# LPC43xx register map
File version: 5
Registers are 32-bit, read-write, reset 0x0 unless marked. A register's access mark holds for its fields unless they carry their own. Offsets are from the block's base; [hi:lo] are bit positions; {n}, {i} and the like mark numbered series.

## SGPIO — Product name title=UM10503 Chapter title=LPC43xx Serial GPIO (SGPIO) Modification date=10/7/2011 Major revision=0 Minor revision=3
Base 0x40101000
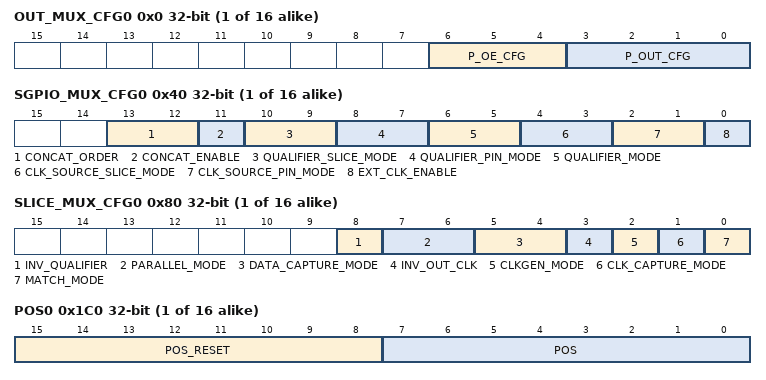
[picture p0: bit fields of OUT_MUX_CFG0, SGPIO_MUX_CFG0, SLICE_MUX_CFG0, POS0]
{0x0+4i} OUT_MUX_CFG{i} (i=0..15) — Pin multiplexer configuration registers.
  [6:4] P_OE_CFG — Output enable source. All other values are reserved.
    0=GPIO_OE_STATE_SET_B (gpio_oe (state set by GPIO_OEREG)); 4=DOUT_OEM1_1_BIT_MOD (dout_oem1 (1-bit mode)); 5=DOUT_OEM2_2_BIT_MOD (dout_oem2 (2-bit mode)); 6=DOUT_OEM4_4_BIT_MOD (dout_oem4 (4-bit mode)); 7=DOUT_OEM8_8_BIT_MOD (dout_oem8 (8-bit mode))
  [3:0] P_OUT_CFG — Output control of output SGPIOn. All other values are reserved.
    0=DOUT_DOUTM1_1_BIT_M (dout_doutm1 (1-bit mode)); 1=DOUT_DOUTM2A_2_BIT_ (dout_doutm2a (2-bit mode 2a)); 2=DOUT_DOUTM2B_2_BIT_ (dout_doutm2b (2-bit mode 2b)); 3=DOUT_DOUTM2C_2_BIT_ (dout_doutm2c (2-bit mode 2c)); 4=GPIO_OUT_LEVEL_SET_ (gpio_out (level set by GPIO_OUTREG)); 5=DOUT_DOUTM4A_4_BIT_ (dout_doutm4a (4-bit mode 4a)); 6=DOUT_DOUTM4B_4_BIT_ (dout_doutm4b (4-bit mode 4b)); 7=DOUT_DOUTM4C_4_BIT_ (dout_doutm4c (4-bit mode 4c)); 8=CLK_OUT; 9=DOUT_DOUTM8A_8_BIT_ (dout_doutm8a (8-bit mode 8a)); 10=DOUT_DOUTM8B_8_BIT_ (dout_doutm8b (8-bit mode 8b)); 11=DOUT_DOUTM8C_8_BIT_ (dout_doutm8c (8-bit mode 8c))
{0x40+4i} SGPIO_MUX_CFG{i} (i=0..15) — SGPIO multiplexer configuration registers.
  [13:12] CONCAT_ORDER — Select concatenation order
    0=SELF_LOOP; 1=2_SLICES; 2=4_SLICES; 3=8_SLICES
  [11] CONCAT_ENABLE — Enable concatenation.
    0=EXTERNAL_DATA_PIN; 1=CONCATENATE_DATA
  [10:9] QUALIFIER_SLICE_MODE — Select qualifier slice.
    0=SLICE_A (Slice A, but for slice A slice D is used.); 1=SLICE_H (Slice H, but for slice H slice O is used.); 2=SLICE_I (Slice I, but for slice I slice D is used.); 3=SLICE_P (Slice P, but for slice P slice O is used.)
  [8:7] QUALIFIER_PIN_MODE — Select qualifier pin.
    {v}=SGPIO{v+8} (v=0..3)
  [6:5] QUALIFIER_MODE — Select qualifier mode.
    0=ENABLE; 1=DISABLE; 2=SLICE_SEE_BITS_QUAL (Slice (see bits QUALIFIER_SLICE_MODE in this register)); 3=EXTERNAL_SGPIO_PIN_ (External SGPIO pin (8, 9, 10, or 11))
  [4:3] CLK_SOURCE_SLICE_MODE — Select clock source slice. Note that slices D, H, O and P do not support this mode.
    0=SLICE_D; 1=SLICE_H; 2=SLICE_O; 3=SLICE_P
  [2:1] CLK_SOURCE_PIN_MODE — Select source clock pin.
    {v}=SGPIO{v+8} (v=0..3)
  [0] EXT_CLK_ENABLE — Select clock signal.
    0=INTERNAL_CLOCK_SIGNA (Internal clock signal (slice)); 1=EXTERNAL_CLOCK_SIGNA (External clock signal (pin))
{0x80+4i} SLICE_MUX_CFG{i} (i=0..15) — Slice multiplexer configuration registers.
  [8] INV_QUALIFIER — Inversion qualifier
    0=USE_NORMAL_QUALIFIER; 1=USE_INVERTED_QUALIFI (Use inverted qualifier.)
  [7:6] PARALLEL_MODE
    0=SHIFT_1_BIT_PER_CLOC (Shift 1 bit per clock.); 1=SHIFT_2_BITS_PER_CLO (Shift 2 bits per clock.); 2=SHIFT_4_BITS_PER_CLO (Shift 4 bits per clock.); 3=SHIFT_1_BYTE_PER_CLO (Shift 1 byte per clock.)
  [5:4] DATA_CAPTURE_MODE — Condition for input bit match interrupt
    0=DETECT_RISING_EDGE_; 1=DETECT_FALLING_EDGE_; 2=DETECT_LOW_LEVEL_; 3=DETECT_HIGH_LEVEL_
  [3] INV_OUT_CLK — Invert output clock
    0=NORMAL_CLOCK_; 1=INVERTED_CLOCK_
  [2] CLKGEN_MODE — Clock generation mode
    0=USE_CLOCK_INTERNALLY (Use clock internally generated by COUNTER.); 1=USE_EXTERNAL_CLOCK_F (Use external clock from a pin or other slice.)
  [1] CLK_CAPTURE_MODE — Capture clock mode
    0=USE_RISING_CLOCK_EDG (Use rising clock edge.); 1=USE_FALLING_CLOCK_ED (Use falling clock edge.)
  [0] MATCH_MODE
    0=DO_NOT_MATCH_DATA_; 1=MATCH_DATA_
{0xC0+4i} REG{i} (i=0..15) — Slice data registers. Each time COUNT0 reaches 0x0 the register shifts loading bit 31 with data captured from DIN(n). DOUT(n) is set to REG(0)
  [31:0] REG — At each active shift clock the register shifts right; loading REG(31) with data captured from DIN(n) and DOUT(n) is set to REG(0).
{0x100+4i} REG_SS{i} (i=0..15) — Slice data shadow registers. Each time POS reaches 0x0 the contents of REG_SS is exchanged with the content of REG
  [31:0] REG_SS — Each time POS reaches 0x0 the contents of REG_SS is exchanged with the content of REG.
{0x140+4i} PRESET{i} (i=0..15) — Reload value of COUNT0, loaded when COUNT0 reaches 0x0
  [11:0] PRESET — Counter reload value; loaded when COUNT reaches 0x0.
{0x180+4i} COUNT{i} (i=0..15) — Down counter, counts down each clock cycle.
  [11:0] COUNT — Down counter, counts down each shift clock cycle. Next count after 0x0 is PRESET.
{0x1C0+4i} POS{i} (i=0..15) — Each time COUNT0 reaches 0x0
  [15:8] POS_RESET — Reload value for POS after POS reaches 0x0.
  [7:0] POS — Each time COUNT reaches 0x0 POS counts down.
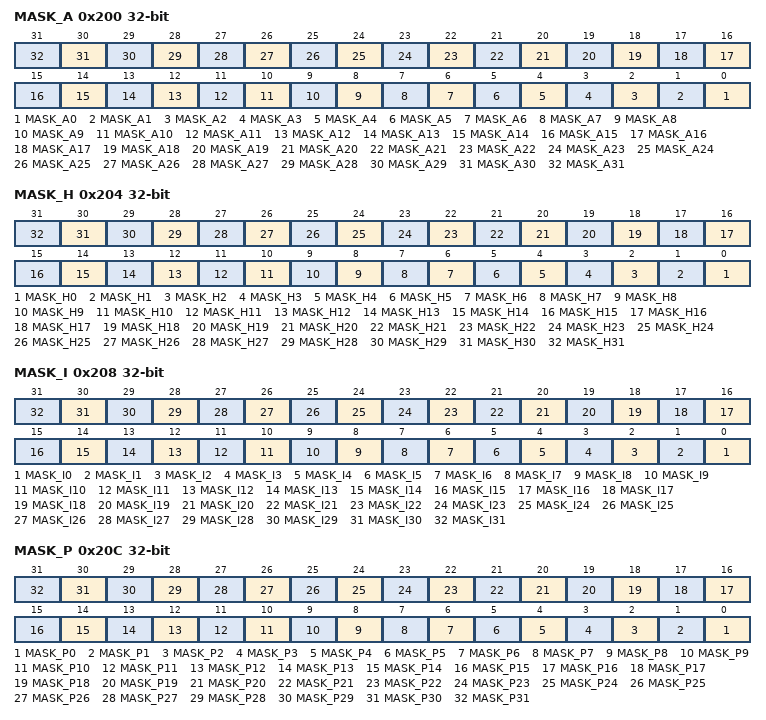
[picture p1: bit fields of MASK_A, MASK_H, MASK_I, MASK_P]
0x200 MASK_A — Mask for pattern match function of slice A
  [n] MASK_A{n} (n=0..31) — Mask for pattern match function of slice A 0 = No effect. 1 = Mask this bit.
0x204 MASK_H — Mask for pattern match function of slice H
  [n] MASK_H{n} (n=0..31) — Mask for pattern match function of slice H 0 = No effect. 1 = Mask this bit.
0x208 MASK_I — Mask for pattern match function of slice I
  [n] MASK_I{n} (n=0..31) — Mask for pattern match function of slice I 0 = No effect . 1 = Mask this bit.
0x20C MASK_P — Mask for pattern match function of slice P
  [n] MASK_P{n} (n=0..31) — Mask for pattern match function of slice P 0 = No effect. 1 = Mask this bit.
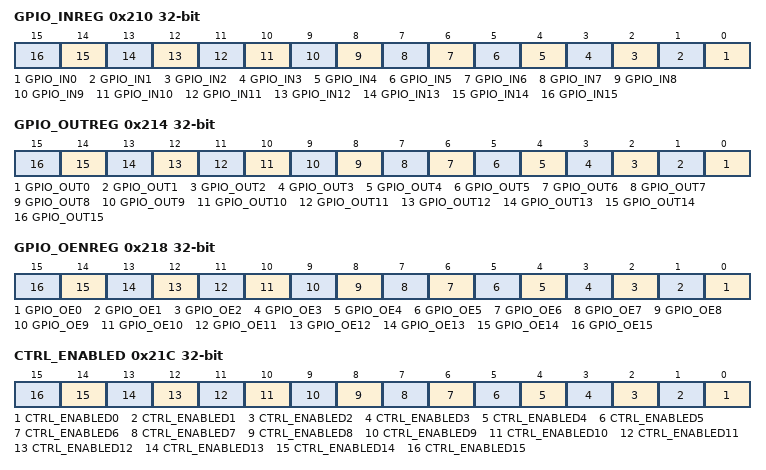
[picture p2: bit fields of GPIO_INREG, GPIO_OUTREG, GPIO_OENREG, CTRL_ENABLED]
0x210 GPIO_INREG ro — GPIO input status register
  [n] GPIO_IN{n} (n=0..15) — Bit i reflects the input state of SGPIO pin i . 0 = LOW 1 = HIGH
0x214 GPIO_OUTREG — GPIO output control register
  [n] GPIO_OUT{n} (n=0..15) — GPIO output register. Bit i sets the output of SGPIO pin i. 0 = LOW 1 = HIGH
0x218 GPIO_OENREG — GPIO OE control register
  [n] GPIO_OE{n} (n=0..15) — Bit i selects the output enable state of SGPIO pin i. 0 = GPIO output i is tri-state . 1 = GPIO output i is active.
0x21C CTRL_ENABLED — Enables the slice COUNT counter
  [n] CTRL_ENABLED{n} (n=0..15) — Slice count enable. Bit n controls slice n (0 = slice A, ..., 15 = slice P). 0 = . 1 = Enables COUNTn.
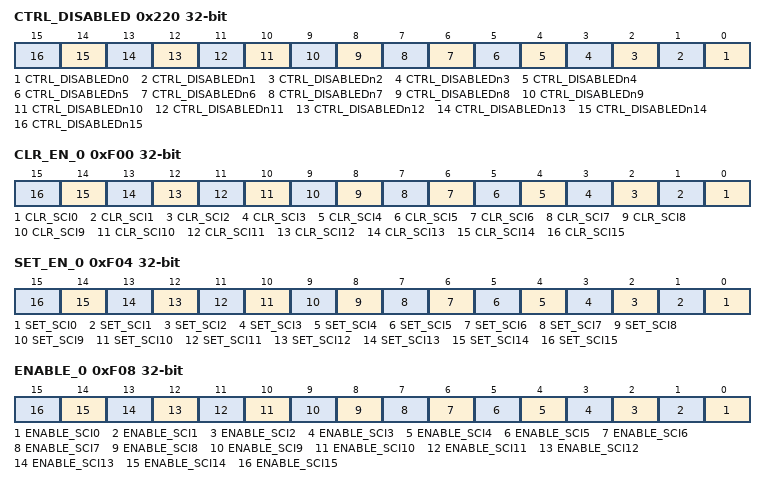
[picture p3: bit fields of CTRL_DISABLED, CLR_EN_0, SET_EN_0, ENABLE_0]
0x220 CTRL_DISABLED — Disables the slice COUNT counter
  [n] CTRL_DISABLEDn{n} (n=0..15) — Slice count disable. Bit n controls slice n, (0 = slice A, ..., 15 = slice P). 0 = 1 = Disables COUNTn.
0xF00 CLR_EN_0 wo — Shift clock interrupt clear mask
  [n] CLR_SCI{n} (n=0..15) — 1 = Shift clock interrupt clear mask of slice n.
0xF04 SET_EN_0 wo — Shift clock interrupt set mask
  [n] SET_SCI{n} (n=0..15) — 1 = Shift clock interrupt set mask of slice n.
0xF08 ENABLE_0 ro — Shift clock interrupt enable
  [n] ENABLE_SCI{n} (n=0..15) — 1 = Shift clock interrupt enable of slice n.
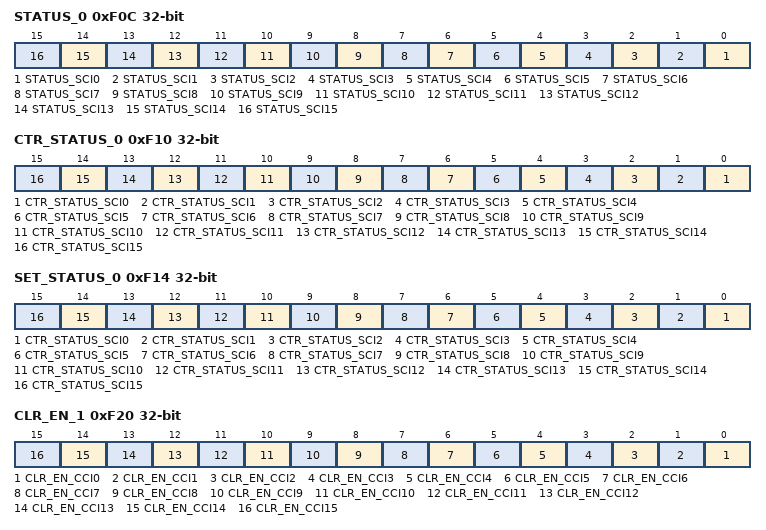
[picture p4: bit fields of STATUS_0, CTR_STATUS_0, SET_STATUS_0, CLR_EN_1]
0xF0C STATUS_0 ro — Shift clock interrupt status
  [n] STATUS_SCI{n} (n=0..15) — Shift clock interrupt status of slice n.
0xF10 CTR_STATUS_0 wo — Shift clock interrupt clear status
  [n] CTR_STATUS_SCI{n} (n=0..15) — Shift clock interrupt clear status of slice n.
0xF14 SET_STATUS_0 wo — Shift clock interrupt set status
  [n] CTR_STATUS_SCI{n} (n=0..15) — Shift clock interrupt set status of slice n.
0xF20 CLR_EN_1 wo — Capture clock interrupt clear mask
  [n] CLR_EN_CCI{n} (n=0..15) — 1 = Capture clock interrupt clear mask of slice n.
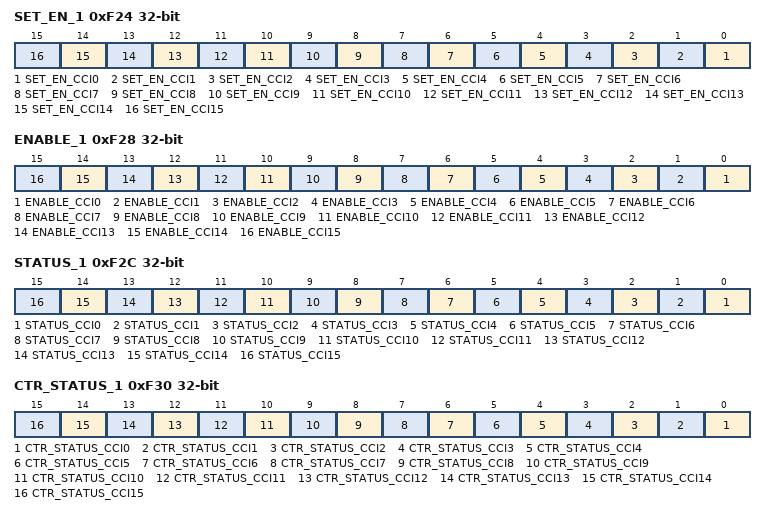
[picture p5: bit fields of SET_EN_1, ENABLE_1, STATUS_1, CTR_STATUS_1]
0xF24 SET_EN_1 wo — Capture clock interrupt set mask
  [n] SET_EN_CCI{n} (n=0..15) — 1 = Capture clock interrupt set mask of slice n.
0xF28 ENABLE_1 ro — Capture clock interrupt enable
  [n] ENABLE_CCI{n} (n=0..15) — Capture clock interrupt enable of slice n.
0xF2C STATUS_1 ro — Capture clock interrupt status
  [n] STATUS_CCI{n} (n=0..15) — Capture clock interrupt status of slice n.
0xF30 CTR_STATUS_1 wo — Capture clock interrupt clear status
  [n] CTR_STATUS_CCI{n} (n=0..15) — Capture clock interrupt clear status of slice n.
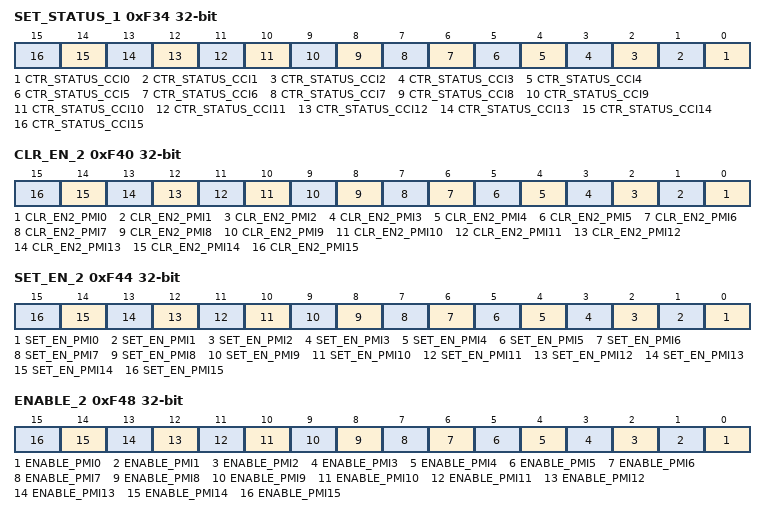
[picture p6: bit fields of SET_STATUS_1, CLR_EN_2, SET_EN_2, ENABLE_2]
0xF34 SET_STATUS_1 wo — Capture clock interrupt set status
  [n] CTR_STATUS_CCI{n} (n=0..15) — Capture clock interrupt set status of slice n.
0xF40 CLR_EN_2 wo — Pattern match interrupt clear mask
  [n] CLR_EN2_PMI{n} (n=0..15) — 1 = Match interrupt clear mask of slice n.
0xF44 SET_EN_2 wo — Pattern match interrupt set mask
  [n] SET_EN_PMI{n} (n=0..15) — 1 = Match interrupt set mask of slice n.
0xF48 ENABLE_2 ro — Pattern match interrupt enable
  [n] ENABLE_PMI{n} (n=0..15) — Match interrupt enable of slice n.
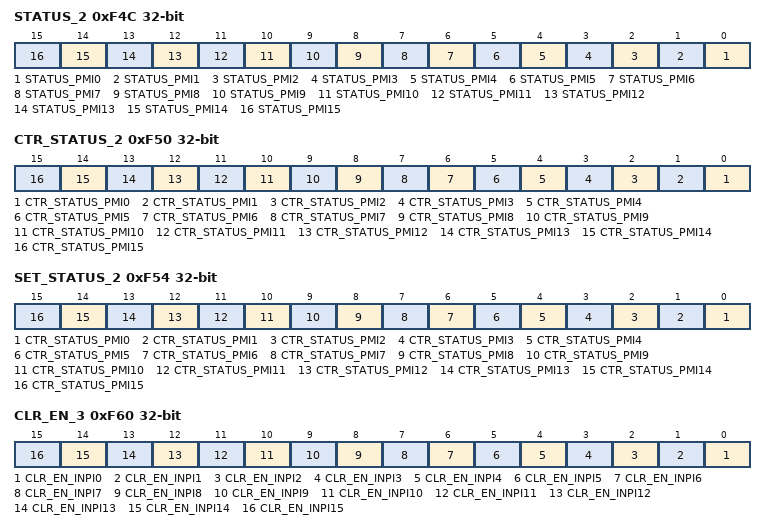
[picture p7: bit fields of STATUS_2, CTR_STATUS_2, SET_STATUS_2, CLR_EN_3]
0xF4C STATUS_2 ro — Pattern match interrupt status
  [n] STATUS_PMI{n} (n=0..15) — Match interrupt status of slice n.
0xF50 CTR_STATUS_2 wo — Pattern match interrupt clear status
  [n] CTR_STATUS_PMI{n} (n=0..15) — Match interrupt clear status of slice n.
0xF54 SET_STATUS_2 wo — Pattern match interrupt set status
  [n] CTR_STATUS_PMI{n} (n=0..15) — Match interrupt set status of slice n.
0xF60 CLR_EN_3 wo — Input interrupt clear mask
  [n] CLR_EN_INPI{n} (n=0..15) — 1 = Input interrupt clear mask of slice n.
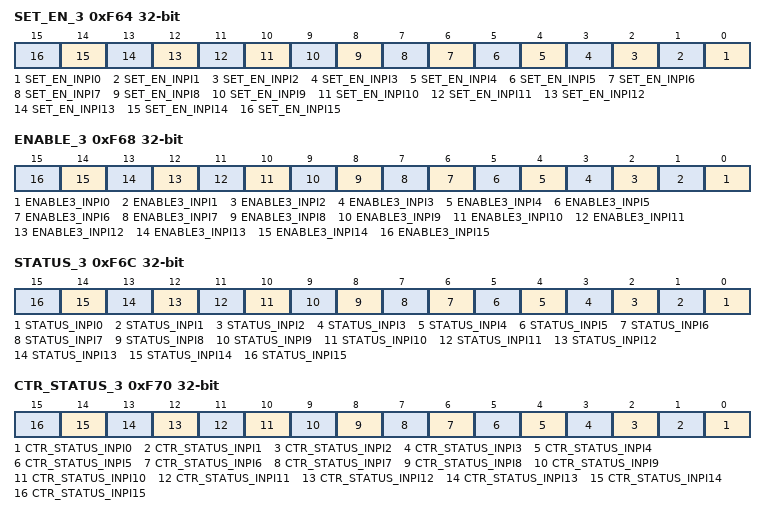
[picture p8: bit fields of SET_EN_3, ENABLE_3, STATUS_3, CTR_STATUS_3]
0xF64 SET_EN_3 wo — Input bit match interrupt set mask
  [n] SET_EN_INPI{n} (n=0..15) — 1 = Input interrupt set mask of slice n.
0xF68 ENABLE_3 ro — Input bit match interrupt enable
  [n] ENABLE3_INPI{n} (n=0..15) — Input interrupt enable of slice n.
0xF6C STATUS_3 ro — Input bit match interrupt status
  [n] STATUS_INPI{n} (n=0..15) — Input interrupt status of slice n.
0xF70 CTR_STATUS_3 wo — Input bit match interrupt clear status
  [n] CTR_STATUS_INPI{n} (n=0..15) — Input interrupt clear status of slice n.
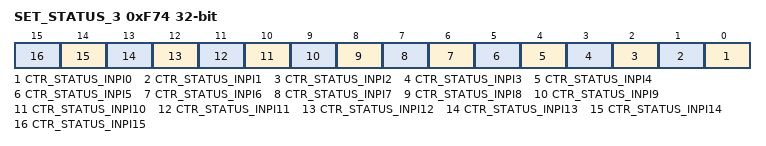
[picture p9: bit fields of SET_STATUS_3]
0xF74 SET_STATUS_3 wo — Shift clock interrupt set status
  [n] CTR_STATUS_INPI{n} (n=0..15) — Shift interrupt set status of slice n.
